LIN_description_file;
LIN_protocol_version = "2.1";
LIN_language_version = "2.1";
LIN_speed = 19.2 kbps;

Nodes {
  Master: BCM_MASTER_NODE, 1 ms, 0 ms ;
  Slaves: RLS_SLAVE_NODE ;
}

Signals {
  BCM_AutoWipersThreshold: 3, 0, BCM_MASTER_NODE, RLS_SLAVE_NODE ;
  BCM_AmbientLightOn: 1, 0, BCM_MASTER_NODE, RLS_SLAVE_NODE ;
  RLS_FrontWipersMode: 2, 0, RLS_SLAVE_NODE, BCM_MASTER_NODE ;
  SIG_Error: 1, 0, RLS_SLAVE_NODE, BCM_MASTER_NODE ;
  RLS_FrontWipersAutoModeEnabled: 1, 0, RLS_SLAVE_NODE, BCM_MASTER_NODE ;
  RLS_AutoLightOn_0: 2, 0, RLS_SLAVE_NODE, BCM_MASTER_NODE ;
  RLS_AutoLightOn_1: 1, 0, RLS_SLAVE_NODE, BCM_MASTER_NODE ;
  RLS_Unknown_1: 1, 1, RLS_SLAVE_NODE, BCM_MASTER_NODE ;
  RLS_AmbientLightLevel_0_3: 2, 0, RLS_SLAVE_NODE, BCM_MASTER_NODE ;
  RLS_Unknown_0: 2, 0, RLS_SLAVE_NODE, BCM_MASTER_NODE ;
  RLS_Unknown_2: 1, 0, RLS_SLAVE_NODE, BCM_MASTER_NODE ;
  RLS_AmbientLightLevel: 7, 0, RLS_SLAVE_NODE, BCM_MASTER_NODE ;
  BCM_WipersSwPos: 3, 0, BCM_MASTER_NODE, RLS_SLAVE_NODE ;
  BCM_Washer: 2, 0, BCM_MASTER_NODE, RLS_SLAVE_NODE ;
  BCM_LightSwitchPos: 3, 0, BCM_MASTER_NODE, RLS_SLAVE_NODE ;
  BCM_Unknown: 1, 0, BCM_MASTER_NODE, RLS_SLAVE_NODE ;
  BCM_VehicleSpeed_L: 4, 0, BCM_MASTER_NODE, RLS_SLAVE_NODE ;
  BCM_VehicleSpeed_H: 8, 0, BCM_MASTER_NODE, RLS_SLAVE_NODE ;
  BCM_BatteryVoltage: 8, 0, BCM_MASTER_NODE, RLS_SLAVE_NODE ;
  RLS_LinError: 1, 0, RLS_SLAVE_NODE, BCM_MASTER_NODE ;
  BCM_11_Unk_0: 2, 0, BCM_MASTER_NODE, RLS_SLAVE_NODE ;
  BCM_11_Unk_1: 1, 0, BCM_MASTER_NODE, RLS_SLAVE_NODE ;
  BCM_11_Unk_2: 8, 0, BCM_MASTER_NODE, RLS_SLAVE_NODE ;
}

Frames {
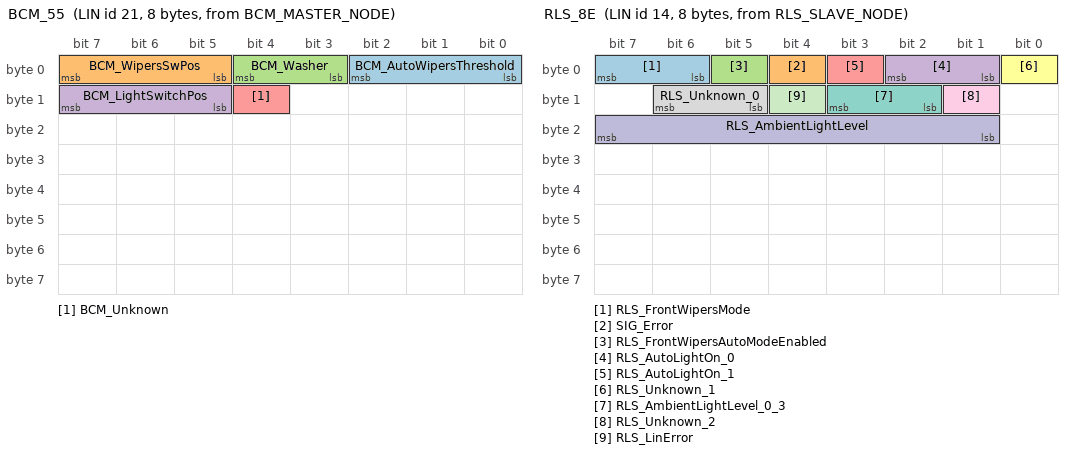
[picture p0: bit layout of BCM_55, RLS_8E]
  BCM_55: 21, BCM_MASTER_NODE, 8 {
    BCM_AutoWipersThreshold, 0 ;
    BCM_WipersSwPos, 5 ;
    BCM_Washer, 3 ;
    BCM_LightSwitchPos, 13 ;
    BCM_Unknown, 12 ;
  }
  BCM_D6: 22, BCM_MASTER_NODE, 8 {
    BCM_AmbientLightOn, 2 ;
  }
  RLS_8E: 14, RLS_SLAVE_NODE, 8 {
    RLS_FrontWipersMode, 6 ;
    SIG_Error, 4 ;
    RLS_FrontWipersAutoModeEnabled, 5 ;
    RLS_AutoLightOn_0, 1 ;
    RLS_AutoLightOn_1, 3 ;
    RLS_Unknown_1, 0 ;
    RLS_AmbientLightLevel_0_3, 10 ;
    RLS_Unknown_0, 13 ;
    RLS_Unknown_2, 9 ;
    RLS_AmbientLightLevel, 17 ;
    RLS_LinError, 12 ;
  }
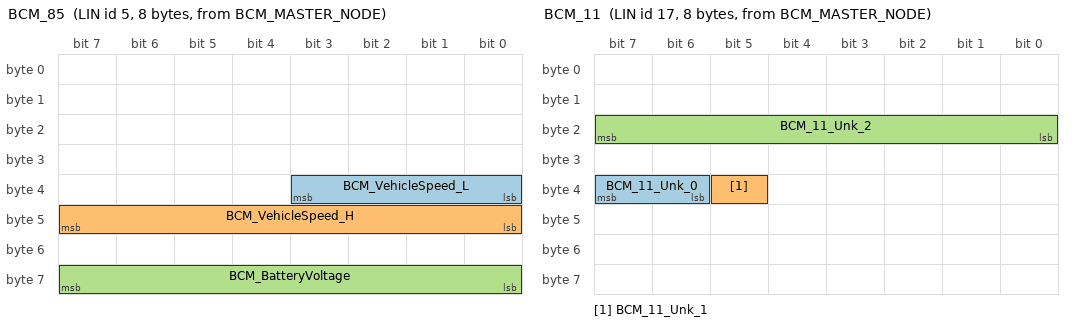
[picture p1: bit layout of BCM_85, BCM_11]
  BCM_85: 5, BCM_MASTER_NODE, 8 {
    BCM_VehicleSpeed_L, 32 ;
    BCM_VehicleSpeed_H, 40 ;
    BCM_BatteryVoltage, 56 ;
  }
  BCM_11: 17, BCM_MASTER_NODE, 8 {
    BCM_11_Unk_0, 38 ;
    BCM_11_Unk_1, 37 ;
    BCM_11_Unk_2, 16 ;
  }
}

Node_attributes {
  RLS_SLAVE_NODE{
    LIN_protocol = "2.1" ;
    configured_NAD = 0x1 ;
    initial_NAD = 0x1 ;
    product_id = 0xFA, 0x1, 0 ;
    response_error = SIG_Error ;
    P2_min = 50 ms ;
    ST_min = 0 ms ;
    N_As_timeout = 1000 ms ;
    N_Cr_timeout = 1000 ms ;
    configurable_frames {
      BCM_55 ;
      RLS_8E ;
      BCM_D6 ;
      BCM_85 ;
      BCM_11 ;
    }
  }
}

Schedule_tables {
 ScheduleTable {
    BCM_11 delay 10 ms ;
    BCM_85 delay 10 ms ;
    SlaveResp delay 10 ms ;
    MasterReq delay 10 ms ;
    RLS_8E delay 10 ms ;
    BCM_D6 delay 10 ms ;
    BCM_55 delay 10 ms ;
  }
}

Signal_encoding_types {
  BCM_BatteryVoltage_Encoding {
    physical_value, 0, 0, 0.1, 0, "V" ;
  }
}

Signal_representation {
  BCM_BatteryVoltage_Encoding: BCM_BatteryVoltage ;
}
